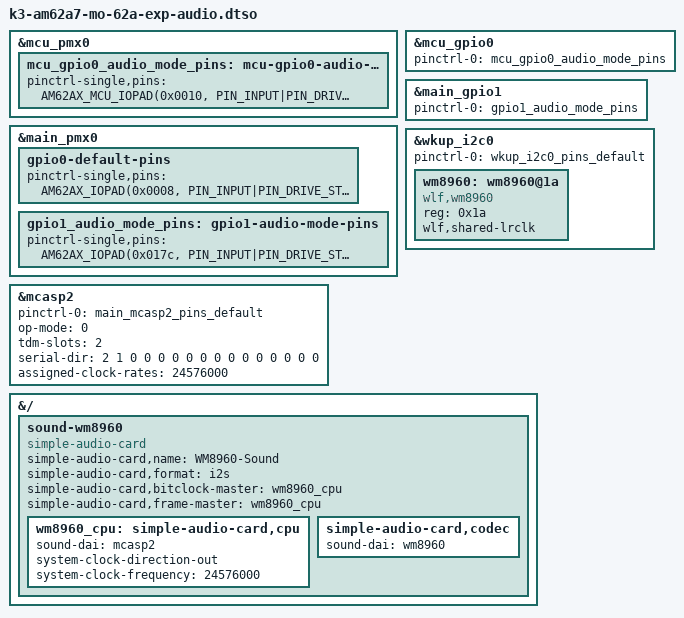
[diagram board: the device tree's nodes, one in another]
// SPDX-License-Identifier: GPL-2.0
/*
 * DT Overlay for MO-62A 40-pin expansion header — WM8960 Audio HAT mode
 *
 * Enables WM8960 Audio HAT using WKUP_I2C0 (codec control) + MCASP2 (I2S data):
 *   Pins  3, 5: WKUP_I2C0 SDA/SCL  (MCU_GPIO0_20/19)  — WM8960 I2C control
 *   Pin  12:    MCASP2_ACLKX        (GPIO1_0)           — I2S BCLK / WM8960 MCLK
 *   Pin  35:    MCASP2_AFSX         (GPIO0_91)          — I2S LRCLK
 *   Pin  38:    MCASP2_AXR0         (GPIO1_5)           — I2S RX (mic from WM8960)
 *   Pin  40:    MCASP2_AXR1         (GPIO1_2)           — I2S TX (playback to WM8960)
 *
 * MCU GPIO0 pinctrl updated to exclude WKUP_I2C0 pins.
 * GPIO1 pinctrl updated to exclude MCASP2 pins (GPIO1_0/2/5).
 * GPIO0 pinctrl updated to exclude MCASP2_AFSX pin (GPIO0_91).
 *
 * Usage: add to extlinux.conf label:
 *   fdtoverlays /ti/k3-am62a7-mo-62a-exp-audio.dtbo
 */

/dts-v1/;
/plugin/;

#include "k3-pinctrl.h"
#define PIN_DRIVE_STRENGTH_NOMINAL 0

/* Reduced MCU GPIO0 pinctrl — excludes WKUP_I2C0 pins (MCU_GPIO0_19/20) */
&mcu_pmx0 {
	mcu_gpio0_audio_mode_pins: mcu-gpio0-audio-mode-pins {
		pinctrl-single,pins = <
			AM62AX_MCU_IOPAD(0x0010, PIN_INPUT|PIN_DRIVE_STRENGTH_NOMINAL, 7) /* MCU_GPIO0_4 */
			/* MCU_GPIO0_19 (0x004c) excluded — claimed by wkup_i2c0 SCL */
			/* MCU_GPIO0_20 (0x0050) excluded — claimed by wkup_i2c0 SDA */
		>;
	};
};

&main_pmx0 {
	/* Reduced GPIO0 pinctrl — excludes MCASP2_AFSX pin (GPIO0_91/0x0174) */
	gpio0-default-pins {
		pinctrl-single,pins = <
			AM62AX_IOPAD(0x0008, PIN_INPUT|PIN_DRIVE_STRENGTH_NOMINAL, 7) /* GPIO0_2 */
			AM62AX_IOPAD(0x002c, PIN_INPUT|PIN_DRIVE_STRENGTH_NOMINAL, 7) /* GPIO0_11 */
			AM62AX_IOPAD(0x0030, PIN_INPUT|PIN_DRIVE_STRENGTH_NOMINAL, 7) /* GPIO0_12 */
			AM62AX_IOPAD(0x0038, PIN_INPUT|PIN_DRIVE_STRENGTH_NOMINAL, 7) /* GPIO0_14 EXP Pin22 */
			AM62AX_IOPAD(0x0088, PIN_INPUT|PIN_DRIVE_STRENGTH_NOMINAL, 7) /* GPIO0_33 EXP Pin31 */
			AM62AX_IOPAD(0x0094, PIN_INPUT|PIN_DRIVE_STRENGTH_NOMINAL, 7) /* GPIO0_36 EXP Pin29 */
			AM62AX_IOPAD(0x009c, PIN_INPUT|PIN_DRIVE_STRENGTH_NOMINAL, 7) /* GPIO0_38 EXP Pin16 */
			AM62AX_IOPAD(0x00a0, PIN_INPUT|PIN_DRIVE_STRENGTH_NOMINAL, 7) /* GPIO0_39 EXP Pin7 */
			AM62AX_IOPAD(0x00a4, PIN_INPUT|PIN_DRIVE_STRENGTH_NOMINAL, 7) /* GPIO0_40 EXP Pin18 */
			AM62AX_IOPAD(0x00a8, PIN_INPUT|PIN_DRIVE_STRENGTH_NOMINAL, 7) /* GPIO0_41 EXP Pin37 */
			AM62AX_IOPAD(0x00ac, PIN_INPUT|PIN_DRIVE_STRENGTH_NOMINAL, 7) /* GPIO0_42 EXP Pin13 */
			AM62AX_IOPAD(0x0164, PIN_INPUT|PIN_DRIVE_STRENGTH_NOMINAL, 7) /* GPIO0_87 CSI0_XSHUTDOWN */
			AM62AX_IOPAD(0x0168, PIN_OUTPUT_PULLDOWN, 7)                  /* GPIO0_88 EXP_3V3_EN */
			AM62AX_IOPAD(0x016c, PIN_INPUT|PIN_DRIVE_STRENGTH_NOMINAL, 7) /* GPIO0_89 */
			AM62AX_IOPAD(0x0170, PIN_INPUT|PIN_DRIVE_STRENGTH_NOMINAL, 7) /* GPIO0_90 SiI9022_INT */
			/* GPIO0_91 (0x0174) excluded — claimed by MCASP2_AFSX */
		>;
	};

	/* Reduced GPIO1 pinctrl — excludes MCASP2 pins (GPIO1_0/2/5) */
	gpio1_audio_mode_pins: gpio1-audio-mode-pins {
		pinctrl-single,pins = <
			/* GPIO1_0  (0x0178) excluded — claimed by MCASP2_ACLKX */
			AM62AX_IOPAD(0x017c, PIN_INPUT|PIN_DRIVE_STRENGTH_NOMINAL, 7) /* GPIO1_1  AUD_RSTn */
			/* GPIO1_2  (0x0180) excluded — claimed by MCASP2_AXR1 */
			AM62AX_IOPAD(0x0188, PIN_INPUT|PIN_DRIVE_STRENGTH_NOMINAL, 7) /* GPIO1_4 */
			/* GPIO1_5  (0x018c) excluded — claimed by MCASP2_AXR0 */
			AM62AX_IOPAD(0x0190, PIN_INPUT|PIN_DRIVE_STRENGTH_NOMINAL, 7) /* GPIO1_6  ETHINTn */
			AM62AX_IOPAD(0x0194, PIN_INPUT, 7)                             /* GPIO1_7  EEP_WC */
			AM62AX_IOPAD(0x019c, PIN_INPUT|PIN_DRIVE_STRENGTH_NOMINAL, 7) /* GPIO1_9 */
			AM62AX_IOPAD(0x01ac, PIN_INPUT|PIN_DRIVE_STRENGTH_NOMINAL, 7) /* GPIO1_13 EXP Pin33 */
			AM62AX_IOPAD(0x01b0, PIN_INPUT|PIN_DRIVE_STRENGTH_NOMINAL, 7) /* GPIO1_14 EXP Pin32 */
			AM62AX_IOPAD(0x01b4, PIN_INPUT|PIN_DRIVE_STRENGTH_NOMINAL, 7) /* GPIO1_15 EXP Pin24 */
			AM62AX_IOPAD(0x01b8, PIN_INPUT|PIN_DRIVE_STRENGTH_NOMINAL, 7) /* GPIO1_16 EXP Pin26 */
			AM62AX_IOPAD(0x01bc, PIN_INPUT|PIN_DRIVE_STRENGTH_NOMINAL, 7) /* GPIO1_17 EXP Pin23 */
			AM62AX_IOPAD(0x01c0, PIN_INPUT|PIN_DRIVE_STRENGTH_NOMINAL, 7) /* GPIO1_18 EXP Pin19 */
			AM62AX_IOPAD(0x01c4, PIN_INPUT|PIN_DRIVE_STRENGTH_NOMINAL, 7) /* GPIO1_19 EXP Pin21 */
			AM62AX_IOPAD(0x01d0, PIN_INPUT|PIN_DRIVE_STRENGTH_NOMINAL, 7) /* GPIO1_22 EXP Pin15 */
			AM62AX_IOPAD(0x01d4, PIN_INPUT|PIN_DRIVE_STRENGTH_NOMINAL, 7) /* GPIO1_23 EXP Pin11 */
			AM62AX_IOPAD(0x01d8, PIN_INPUT|PIN_DRIVE_STRENGTH_NOMINAL, 7) /* GPIO1_24 EXP Pin10 */
			AM62AX_IOPAD(0x01dc, PIN_INPUT|PIN_DRIVE_STRENGTH_NOMINAL, 7) /* GPIO1_25 EXP Pin8 */
			AM62AX_IOPAD(0x01f4, PIN_INPUT|PIN_DRIVE_STRENGTH_NOMINAL, 7) /* GPIO1_31 EXTINTn */
		>;
	};
};

&mcu_gpio0 {
	pinctrl-names = "default";
	pinctrl-0 = <&mcu_gpio0_audio_mode_pins>;
};

&main_gpio1 {
	pinctrl-names = "default";
	pinctrl-0 = <&gpio1_audio_mode_pins>;
};

/* Pins 3,5 — WKUP_I2C0 SDA/SCL + WM8960 Audio HAT */
&wkup_i2c0 {
	status = "okay";
	pinctrl-names = "default";
	pinctrl-0 = <&wkup_i2c0_pins_default>;

	wm8960: wm8960@1a {
		compatible = "wlf,wm8960";
		reg = <0x1a>;
		#sound-dai-cells = <0>;
		wlf,shared-lrclk;
	};
};

/* Pins 12,35,38,40 — MCASP2 I2S master for WM8960 Audio HAT
 * Pin 12 = ACLKX (BCLK, also used as WM8960 MCLK)
 * Pin 35 = AFSX  (LRCLK)
 * Pin 38 = AXR0  (RX: mic data from WM8960 to SoC)
 * Pin 40 = AXR1  (TX: playback data from SoC to WM8960)
 */
&mcasp2 {
	status = "okay";
	#sound-dai-cells = <0>;
	pinctrl-names = "default";
	pinctrl-0 = <&main_mcasp2_pins_default>;
	op-mode = <0>;          /* MCASP_IIS_MODE */
	tdm-slots = <2>;
	serial-dir = <          /* 0: INACTIVE, 1: TX, 2: RX */
		2 1 0 0
		0 0 0 0
		0 0 0 0
		0 0 0 0
	>;
	/* Set fck to exact audio clock: 24.576 MHz = 512 × 48 kHz */
	assigned-clock-rates = <24576000>;
};

/* ASoC sound card: MCASP2 (I2S master) + WM8960 (codec slave) */
&{/} {
	sound-wm8960 {
		compatible = "simple-audio-card";
		simple-audio-card,name = "WM8960-Sound";
		simple-audio-card,format = "i2s";
		simple-audio-card,bitclock-master = <&wm8960_cpu>;
		simple-audio-card,frame-master = <&wm8960_cpu>;

		wm8960_cpu: simple-audio-card,cpu {
			sound-dai = <&mcasp2>;
			system-clock-direction-out;
			system-clock-frequency = <24576000>;
		};

		simple-audio-card,codec {
			sound-dai = <&wm8960>;
		};
	};
};
